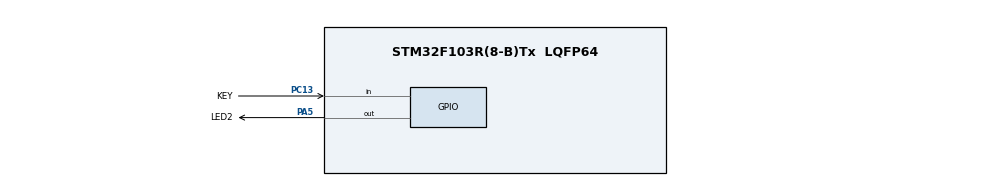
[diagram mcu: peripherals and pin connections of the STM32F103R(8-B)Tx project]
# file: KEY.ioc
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Mcu.Family=STM32F1
Mcu.Name=STM32F103R(8-B)Tx
Mcu.Package=LQFP64
NVIC.PriorityGroup=NVIC_PRIORITYGROUP_4
PA5.GPIO_Label=LED2
PA5.GPIO_ModeDefaultOutputPP=GPIO_MODE_OUTPUT_PP
PA5.Signal=GPIO_Output
PC13-TAMPER-RTC.GPIO_Label=KEY
PC13-TAMPER-RTC.GPIO_PuPd=GPIO_PULLUP
PC13-TAMPER-RTC.Signal=GPIO_Input
ProjectManager.HeapSize=0x200
ProjectManager.StackSize=0x400
ProjectManager.TargetToolchain=MDK-ARM V5
RCC.APB1Freq_Value=8000000
RCC.APB2Freq_Value=8000000
VP_SYS_VS_ND.Mode=No_Debug
board=custom

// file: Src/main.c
/* USER CODE BEGIN Header */
/**
  ******************************************************************************
  * @file           : main.c
  * @brief          : Main program body
  ******************************************************************************
  * @attention
  *
  * <h2><center>&copy; Copyright (c) 2020 STMicroelectronics.
  * All rights reserved.</center></h2>
  *
  * This software component is licensed by ST under BSD 3-Clause license,
  * the "License"; You may not use this file except in compliance with the
  * License. You may obtain a copy of the License at:
  *                        opensource.org/licenses/BSD-3-Clause
  *
  ******************************************************************************
  */
/* USER CODE END Header */

#include "main.h"
#include "gpio.h"

void SystemClock_Config(void);

int main(void)
{
  /* USER CODE BEGIN 1 */
	unsigned int flag = 0;
  /* USER CODE END 1 */

  /* MCU Configuration--------------------------------------------------------*/

  /* Reset of all peripherals, Initializes the Flash interface and the Systick. */
  HAL_Init();

  /* Configure the system clock */
  SystemClock_Config();

  /* Initialize all configured peripherals */
  MX_GPIO_Init();

  /* Infinite loop */
  while (1)
  {
		if(!key)
		{
			HAL_Delay (10);
			if(!key)
			{
				flag = !flag;
			}
			while(!key);
		}
		if(flag)
		{
			HAL_GPIO_WritePin(GPIOA,GPIO_PIN_5,GPIO_PIN_SET);
		}
		else
			HAL_GPIO_WritePin(GPIOA,GPIO_PIN_5,GPIO_PIN_RESET);

  }
}

void SystemClock_Config(void)
{
  RCC_OscInitTypeDef RCC_OscInitStruct = {0};
  RCC_ClkInitTypeDef RCC_ClkInitStruct = {0};

  /** Initializes the CPU, AHB and APB busses clocks
  */
  RCC_OscInitStruct.OscillatorType = RCC_OSCILLATORTYPE_HSI;
  RCC_OscInitStruct.HSIState = RCC_HSI_ON;
  RCC_OscInitStruct.HSICalibrationValue = RCC_HSICALIBRATION_DEFAULT;
  RCC_OscInitStruct.PLL.PLLState = RCC_PLL_NONE;
  if (HAL_RCC_OscConfig(&RCC_OscInitStruct) != HAL_OK)
  {
    Error_Handler();
  }
  /** Initializes the CPU, AHB and APB busses clocks
  */
  RCC_ClkInitStruct.ClockType = RCC_CLOCKTYPE_HCLK|RCC_CLOCKTYPE_SYSCLK
                              |RCC_CLOCKTYPE_PCLK1|RCC_CLOCKTYPE_PCLK2;
  RCC_ClkInitStruct.SYSCLKSource = RCC_SYSCLKSOURCE_HSI;
  RCC_ClkInitStruct.AHBCLKDivider = RCC_SYSCLK_DIV1;
  RCC_ClkInitStruct.APB1CLKDivider = RCC_HCLK_DIV1;
  RCC_ClkInitStruct.APB2CLKDivider = RCC_HCLK_DIV1;

  if (HAL_RCC_ClockConfig(&RCC_ClkInitStruct, FLASH_LATENCY_0) != HAL_OK)
  {
    Error_Handler();
  }
}

void Error_Handler(void)
{
}

/************************ (C) COPYRIGHT STMicroelectronics *****END OF FILE****/
